# cmem7 register map
File version: 1.0
Registers are 32-bit, read-write, reset 0x0 unless marked. A register's access mark holds for its fields unless they carry their own. Offsets are from the block's base; [hi:lo] are bit positions.

## GLOBAL_CTRL
Base 0x41007010
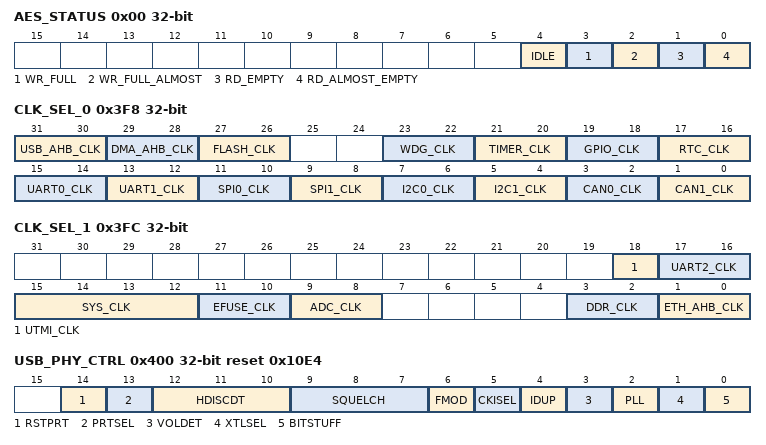
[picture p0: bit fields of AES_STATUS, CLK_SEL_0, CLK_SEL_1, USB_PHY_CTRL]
0x00 AES_STATUS ro
  [4] IDLE — decryption finish
  [3] WR_FULL — FIFO write full
  [2] WR_FULL_ALMOST — FIFO write almost full
  [1] RD_EMPTY — FIFO read empty
  [0] RD_ALMOST_EMPTY — FIFO read almost empty
0x3F8 CLK_SEL_0 — clock select 0
  [31:30] USB_AHB_CLK — USB AHB bus clock frequency dividor based on system clock, which should be 1/1, 1/2, 1/4, 1/8 from 0 to 3
  [29:28] DMA_AHB_CLK — DMA AHB bus clock frequency dividor based on system clock, which should be 1/1, 1/2, 1/4, 1/8 from 0 to 3
  [27:26] FLASH_CLK — FLASH clock frequency dividor based on system clock, which should be 1/1, 1/2, 1/4, 1/8 from 0 to 3
  [23:22] WDG_CLK — watchdog clock frequency dividor based on system clock, which should be 1/2, 1/4, 1/8, 1/16 from 0 to 3
  [21:20] TIMER_CLK — TIMER clock frequency dividor based on system clock, which should be 1/2, 1/4, 1/8, 1/16 from 0 to 3
  [19:18] GPIO_CLK — GPIO clock frequency dividor based on system clock, which should be 1/2, 1/4, 1/8, 1/16 from 0 to 3
  [17:16] RTC_CLK — RTC clock frequency dividor based on system clock, which should be 1/2, 1/4, 1/8, 1/16 from 0 to 3
  [15:14] UART0_CLK — UART0 clock frequency dividor based on system clock, which should be 1/2, 1/4, 1/8, 1/16 from 0 to 3
  [13:12] UART1_CLK — UART1 clock frequency dividor based on system clock, which should be 1/2, 1/4, 1/8, 1/16 from 0 to 3
  [11:10] SPI0_CLK — SPI0 clock frequency dividor based on system clock, which should be 1/2, 1/4, 1/8, 1/16 from 0 to 3
  [9:8] SPI1_CLK — SPI1 clock frequency dividor based on system clock, which should be 1/2, 1/4, 1/8, 1/16 from 0 to 3
  [7:6] I2C0_CLK — I2C0 clock frequency dividor based on system clock, which should be 1/2, 1/4, 1/8, 1/16 from 0 to 3
  [5:4] I2C1_CLK — I2C1 clock frequency dividor based on system clock, which should be 1/2, 1/4, 1/8, 1/16 from 0 to 3
  [3:2] CAN0_CLK — CAN0 clock frequency dividor based on system clock, which should be 1/32, 1/4, 1/8, 1/16 from 0 to 3
  [1:0] CAN1_CLK — CAN1 clock frequency dividor based on system clock, which should be 1/32, 1/4, 1/8, 1/16 from 0 to 3
0x3FC CLK_SEL_1 — clock select 1
  [18] UTMI_CLK — UTMI clock came from on-chip usb phy(0) or off-chip usb phy(1)
  [17:16] UART2_CLK — UART2 clock frequency dividor based on system clock, which should be 1/2, 1/4, 1/8, 1/16 from 0 to 3
  [15:12] SYS_CLK — system clock clock frequency dividor based on system clock, which should be oscillator(0), DLL(1), crystal(2), external(3), JTAG(4), PS(8)
  [11:10] EFUSE_CLK — EFUSE clock frequency dividor based on system clock, which should be 1/2, 1/4, 1/8, 1/16 from 0 to 3
  [9:8] ADC_CLK — ADC clock frequency dividor based on system clock, which should be 1/8, 1/16, 1/32, external from 0 to 3
  [3:2] DDR_CLK — DDR clock frequency dividor based on system clock, which should be 1/1, 1/2, 1/4, 1/8 from 0 to 3
  [1:0] ETH_AHB_CLK — ETH_AHB clock frequency dividor based on system clock, which should be 1/1, 1/2, 1/4, 1/8 from 0 to 3
0x400 USB_PHY_CTRL reset 0x10E4 — USB Phy Control Register
  [14] RSTPRT — 0: The reverse of usb_rst_n will reset, 1: Reset OTG PHY
  [13] PRTSEL — 0: Internal OTG PHY, 1: UTMI to External PHY
  [12:10] HDISCDT — Host Disconnect Detection Reference Voltage, 000: 500mV, 100: 588mV, 111: 654mV
  [9:7] SQUELCH — Squelch Reference Voltage, 000: 27.5mV, 001: 137.5mV, 111: 220mV
  [6] FMOD — 1: Normal
  [5] CKISEL — Clock selection, 0: Crystal, 1: Internal Clock
  [4] IDUP — 0: ID is uplled up through 33k Ohm resister
  [3] VOLDET — Voltage Detector Enable, 0: Disable
  [2] PLL — PLL mode
  [1] XTLSEL — 0: 12MHz
  [0] BITSTUFF — 0: No bit stuff
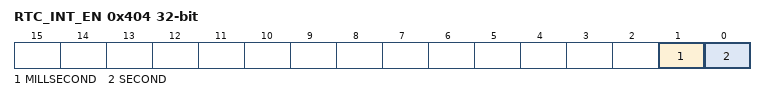
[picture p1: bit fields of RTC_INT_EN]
0x404 RTC_INT_EN — RTC interrupt enable Register
  [1] MILLSECOND — 1ms interrupt enable
  [0] SECOND — 1s interrupt enable
0x40C NMI_SEL — nmi interrupt selection
  [6:0] NMI — NMI interrupt ID
0x414 AES_TARGET_ADDR — AES target address, default is frame decoder address(0x41800000)
0x418 AES_BURST_TYPE
  [1:0] TYPE — burst type, fixed(0), incr(1)
0x428 ICACHE — ICACHE Enable
  [0] EN
0x42C IBUSOFF — Code Bus Offset
0x430 DBUSOFF — Data Bus Offset
0x434 EXTADDR — Bus Ext Addr
